VERSION ""

NS_ :

BS_:

BU_:
	NEO
	MCU
	GTW
	EPAS
	DI
	ESP
	SBW
	STW
	APP
	DAS
	XXX

VAL_TABLE_ StW_AnglHP_Spd 16383 "SNA" ;
VAL_TABLE_ DI_aebFaultReason 15 "DI_AEB_FAULT_DAS_REQ_DI_UNAVAIL" 14 "DI_AEB_FAULT_ACCEL_REQ_INVALID" 13 "DI_AEB_FAULT_MIN_TIME_BTWN_EVENTS" 12 "DI_AEB_FAULT_ESP_MIA" 11 "DI_AEB_FAULT_ESP_FAULT" 10 "DI_AEB_FAULT_EPB_NOT_PARKED" 9 "DI_AEB_FAULT_ACCEL_OUT_OF_BOUNDS" 8 "DI_AEB_FAULT_PM_REQUEST" 7 "DI_AEB_FAULT_VEL_EST_ABNORMAL" 6 "DI_AEB_FAULT_DAS_SNA" 5 "DI_AEB_FAULT_DAS_CONTROL_MIA" 4 "DI_AEB_FAULT_SPEED_DELTA" 3 "DI_AEB_FAULT_EBR_FAULT" 2 "DI_AEB_FAULT_PM_MIA" 1 "DI_AEB_FAULT_EPB_MIA" 0 "DI_AEB_FAULT_NONE" ;
VAL_TABLE_ DI_aebLockState 3 "AEB_LOCK_STATE_SNA" 2 "AEB_LOCK_STATE_UNUSED" 1 "AEB_LOCK_STATE_UNLOCKED" 0 "AEB_LOCK_STATE_LOCKED" ;
VAL_TABLE_ DI_aebSmState 7 "DI_AEB_STATE_FAULT" 6 "DI_AEB_STATE_EXIT" 5 "DI_AEB_STATE_STANDSTILL" 4 "DI_AEB_STATE_STOPPING" 3 "DI_AEB_STATE_ENABLE" 2 "DI_AEB_STATE_ENABLE_INIT" 1 "DI_AEB_STATE_STANDBY" 0 "DI_AEB_STATE_UNAVAILABLE" ;
VAL_TABLE_ DI_aebState 7 "AEB_CAN_STATE_SNA" 4 "AEB_CAN_STATE_FAULT" 3 "AEB_CAN_STATE_STANDSTILL" 2 "AEB_CAN_STATE_ENABLED" 1 "AEB_CAN_STATE_STANDBY" 0 "AEB_CAN_STATE_UNAVAILABLE" ;
VAL_TABLE_ DI_epbInterfaceReady 1 "EPB_INTERFACE_READY" 0 "EPB_INTERFACE_NOT_READY" ;
VAL_TABLE_ DI_gear 7 "DI_GEAR_SNA" 4 "DI_GEAR_D" 3 "DI_GEAR_N" 2 "DI_GEAR_R" 1 "DI_GEAR_P" 0 "DI_GEAR_INVALID" ;
VAL_TABLE_ DI_gpoReason 8 "DI_GPO_NUMREASONS" 7 "DI_GPO_CAPACITOR_OVERTEMP" 6 "DI_GPO_NOT_ENOUGH_12V" 5 "DI_GPO_NO_BATTERY_POWER" 4 "DI_GPO_AMBIENT_OVERTEMP" 3 "DI_GPO_FLUID_DELTAT" 2 "DI_GPO_STATOR_OVERTEMP" 1 "DI_GPO_HEATSINK_OVERTEMP" 0 "DI_GPO_OUTLET_OVERTEMP" ;
VAL_TABLE_ DI_immobilizerCondition 1 "DI_IMM_CONDITION_LEARNED" 0 "DI_IMM_CONDITION_VIRGIN_SNA" ;
VAL_TABLE_ DI_immobilizerState 7 "DI_IMM_STATE_FAULT" 6 "DI_IMM_STATE_FAULTRETRY" 5 "DI_IMM_STATE_RESET" 4 "DI_IMM_STATE_LEARN" 3 "DI_IMM_STATE_DISARMED" 2 "DI_IMM_STATE_AUTHENTICATING" 1 "DI_IMM_STATE_REQUEST" 0 "DI_IMM_STATE_INIT_SNA" ;
VAL_TABLE_ DI_limpReason 24 "DI_LIMP_NUMREASONS" 23 "DI_LIMP_CAPACITOR_OVERTEMP" 22 "DI_LIMP_GTW_MIA" 21 "DI_LIMP_TRQCMD_VALIDITY_UNKNOWN" 20 "DI_LIMP_DI_MIA" 19 "DI_LIMP_CONFIG_MISMATCH" 18 "DI_LIMP_HEATSINK_TEMP" 17 "DI_LIMP_PMREQUEST" 16 "DI_LIMP_PMHEARTBEAT" 15 "DI_LIMP_TRQ_CROSS_CHECK" 14 "DI_LIMP_EXTERNAL_COMMAND" 13 "DI_LIMP_WRONG_CS_CALIBRATION" 12 "DI_LIMP_STATOR_TEMP" 11 "DI_LIMP_DELTAT_TOO_NEGATIVE" 10 "DI_LIMP_DELTAT_TOO_POSITIVE" 9 "DI_LIMP_AMBIENT_TEMP" 8 "DI_LIMP_OUTLET_TEMP" 7 "DI_LIMP_LOW_FLOW" 6 "DI_LIMP_BMS_MIA" 5 "DI_LIMP_12V_SUPPLY_UNDERVOLTAGE" 4 "DI_LIMP_NO_FLUID" 3 "DI_LIMP_NO_FUNC_HEATSINK_SENSOR" 2 "DI_LIMP_NO_FUNC_STATORT_SENSOR" 1 "DI_LIMP_BUSV_SENSOR_IRRATIONAL" 0 "DI_LIMP_PHASE_IMBALANCE" ;
VAL_TABLE_ DI_mode 2 "DI_MODE_DYNO" 1 "DI_MODE_DRIVE" 0 "DI_MODE_UNDEF" ;
VAL_TABLE_ DI_motorType 14 "DI_MOTOR_F2AE" 13 "DI_MOTOR_F2AD" 12 "DI_MOTOR_F2AC" 11 "DI_MOTOR_F2AB" 10 "DI_MOTOR_F1AC" 9 "DI_MOTOR_SSR1A" 8 "DI_MOTOR_F1A" 7 "DI_MOTOR_M7M6" 6 "DI_MOTOR_M8A" 5 "DI_MOTOR_M7M5" 4 "DI_MOTOR_M7M4" 3 "DI_MOTOR_M7M3" 2 "DI_MOTOR_ROADSTER_SPORT" 1 "DI_MOTOR_ROADSTER_BASE" 0 "DI_MOTOR_SNA" ;
VAL_TABLE_ DI_speedUnits 1 "DI_SPEED_KPH" 0 "DI_SPEED_MPH" ;
VAL_TABLE_ DI_state 4 "DI_STATE_ENABLE" 3 "DI_STATE_FAULT" 2 "DI_STATE_CLEAR_FAULT" 1 "DI_STATE_STANDBY" 0 "DI_STATE_PREAUTH" ;
VAL_TABLE_ DI_velocityEstimatorState 4 "VE_STATE_BACKUP_MOTOR" 3 "VE_STATE_BACKUP_WHEELS_B" 2 "VE_STATE_BACKUP_WHEELS_A" 1 "VE_STATE_WHEELS_NORMAL" 0 "VE_STATE_NOT_INITIALIZED" ;

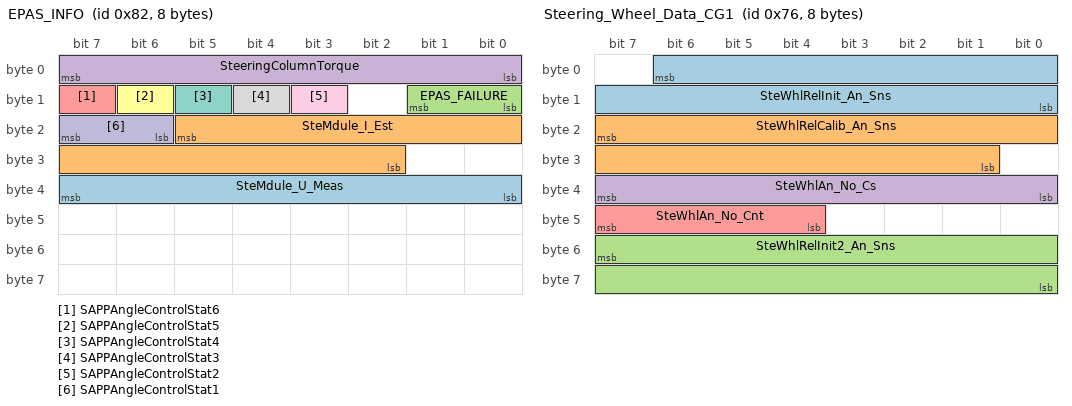
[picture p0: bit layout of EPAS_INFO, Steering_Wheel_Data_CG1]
BO_ 130 EPAS_INFO: 8 XXX
 SG_ SteMdule_U_Meas : 39|8@0+ (0.05,6.0) [0|0] "Volts" XXX
 SG_ SteMdule_I_Est : 21|12@0+ (0.05,-64.0) [0|0] "Amps" XXX
 SG_ EPAS_FAILURE : 9|2@0+ (1,0) [0|0] "" XXX
 SG_ SteeringColumnTorque : 7|8@0+ (0.0625,-8.0) [0|0] "Nm" XXX
 SG_ SAPPAngleControlStat6 : 15|1@0+ (1,0) [0|0] "" XXX
 SG_ SAPPAngleControlStat5 : 14|1@0+ (1,0) [0|0] "" XXX
 SG_ SAPPAngleControlStat4 : 13|1@0+ (1,0) [0|0] "" XXX
 SG_ SAPPAngleControlStat3 : 12|1@0+ (1,0) [0|0] "" XXX
 SG_ SAPPAngleControlStat2 : 11|1@0+ (1,0) [0|0] "" XXX
 SG_ SAPPAngleControlStat1 : 23|2@0+ (1,0) [0|0] "" XXX

BO_ 118 Steering_Wheel_Data_CG1: 8 XXX
 SG_ SteWhlRelInit_An_Sns : 6|15@0+ (0.1,-1600.0) [0|0] "deg" XXX
 SG_ SteWhlRelCalib_An_Sns : 23|15@0+ (0.1,-1600.0) [0|0] "deg" XXX
 SG_ SteWhlRelInit2_An_Sns : 55|16@0+ (0.1,-3200.0) [0|0] "deg" XXX
 SG_ SteWhlAn_No_Cs : 39|8@0+ (1,0) [0|0] "" XXX
 SG_ SteWhlAn_No_Cnt : 47|4@0+ (1,0) [0|0] "Counts" XXX

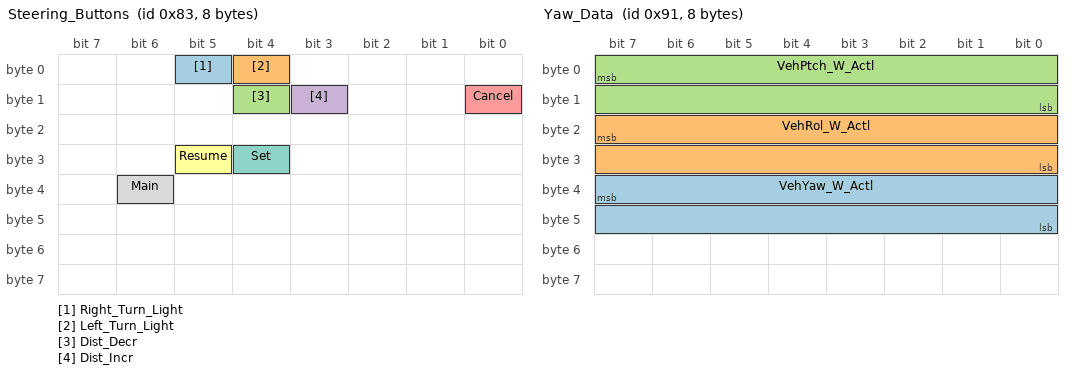
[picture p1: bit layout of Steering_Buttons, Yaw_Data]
BO_ 131 Steering_Buttons: 8 XXX
 SG_ Right_Turn_Light : 5|1@0+ (1,0) [0|0] "" XXX
 SG_ Left_Turn_Light : 4|1@0+ (1,0) [0|0] "" XXX
 SG_ Dist_Decr : 12|1@0+ (1,0) [0|0] "" XXX
 SG_ Dist_Incr : 11|1@0+ (1,0) [0|0] "" XXX
 SG_ Cancel : 8|1@0+ (1,0) [0|0] "" XXX
 SG_ Resume : 29|1@0+ (1,0) [0|0] "" XXX
 SG_ Set : 28|1@0+ (1,0) [0|0] "" XXX
 SG_ Main : 38|1@0+ (1,0) [0|0] "" XXX

BO_ 145 Yaw_Data: 8 XXX
 SG_ VehYaw_W_Actl : 39|16@0+ (0.0002,-6.5) [0|0] "rad/s" XXX
 SG_ VehRol_W_Actl : 23|16@0+ (0.0002,-6.5) [0|0] "rad/s" XXX
 SG_ VehPtch_W_Actl : 7|16@0+ (0.0002,-6.5) [0|0] "rad/s" XXX

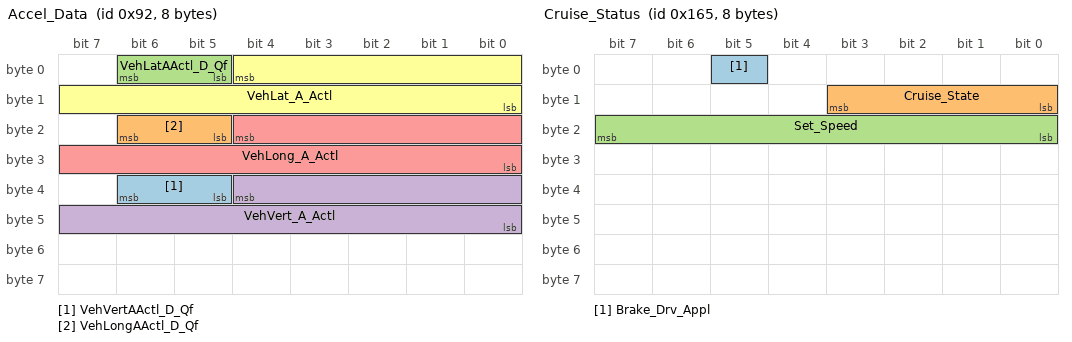
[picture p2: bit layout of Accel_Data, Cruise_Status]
BO_ 146 Accel_Data: 8 XXX
 SG_ VehVertAActl_D_Qf : 38|2@0+ (1,0) [0|0] "" XXX
 SG_ VehLongAActl_D_Qf : 22|2@0+ (1,0) [0|0] "" XXX
 SG_ VehLatAActl_D_Qf : 6|2@0+ (1,0) [0|0] "" XXX
 SG_ VehVert_A_Actl : 36|13@0+ (0.01,-40.0) [0|0] "m/s^2" XXX
 SG_ VehLong_A_Actl : 20|13@0+ (0.01,-40.0) [0|0] "m/s^2" XXX
 SG_ VehLat_A_Actl : 4|13@0+ (0.01,-40.0) [0|0] "m/s^2" XXX

BO_ 357 Cruise_Status: 8 XXX
 SG_ Brake_Drv_Appl : 5|1@0+ (1,0) [0|0] "" XXX
 SG_ Cruise_State : 11|4@0+ (1,0) [0|0] "" XXX
 SG_ Set_Speed : 23|8@0+ (1,0) [0|0] "" XXX

BO_ 516 EngineData_14: 8 XXX
 SG_ ApedPosScal_Pc_Actl : 1|10@0+ (0.1,0) [0|0] "%" XXX

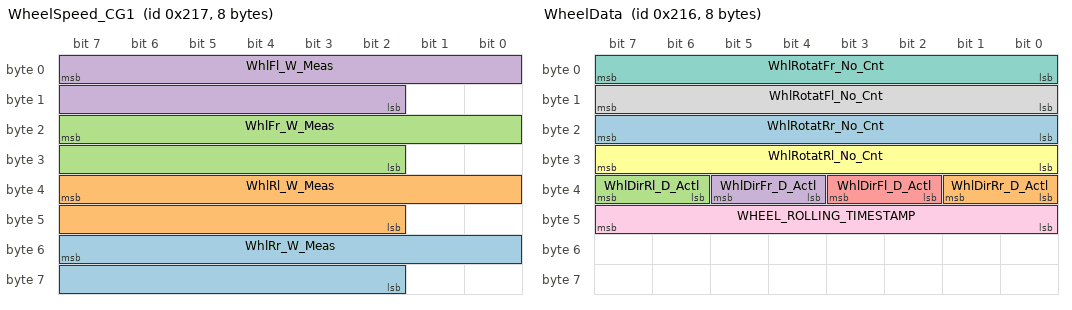
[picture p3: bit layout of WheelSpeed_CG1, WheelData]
BO_ 535 WheelSpeed_CG1: 8 XXX
 SG_ WhlRr_W_Meas : 55|14@0+ (0.04,0) [0|0] "rad/s" XXX
 SG_ WhlRl_W_Meas : 39|14@0+ (0.04,0) [0|0] "rad/s" XXX
 SG_ WhlFr_W_Meas : 23|14@0+ (0.04,0) [0|0] "rad/s" XXX
 SG_ WhlFl_W_Meas : 7|14@0+ (0.04,0) [0|0] "rad/s" XXX

BO_ 534 WheelData: 8 XXX
 SG_ WhlRotatRr_No_Cnt : 23|8@0+ (1,0) [0|0] "" XXX
 SG_ WhlDirRr_D_Actl : 33|2@0+ (1,0) [0|0] "" XXX
 SG_ WhlDirRl_D_Actl : 39|2@0+ (1,0) [0|0] "" XXX
 SG_ WhlDirFr_D_Actl : 37|2@0+ (1,0) [0|0] "" XXX
 SG_ WhlDirFl_D_Actl : 35|2@0+ (1,0) [0|0] "" XXX
 SG_ WhlRotatRl_No_Cnt : 31|8@0+ (1,0) [0|0] "" XXX
 SG_ WhlRotatFr_No_Cnt : 7|8@0+ (1,0) [0|0] "" XXX
 SG_ WhlRotatFl_No_Cnt : 15|8@0+ (1,0) [0|0] "" XXX
 SG_ WHEEL_ROLLING_TIMESTAMP : 47|8@0+ (1,0) [0|0] "" XXX

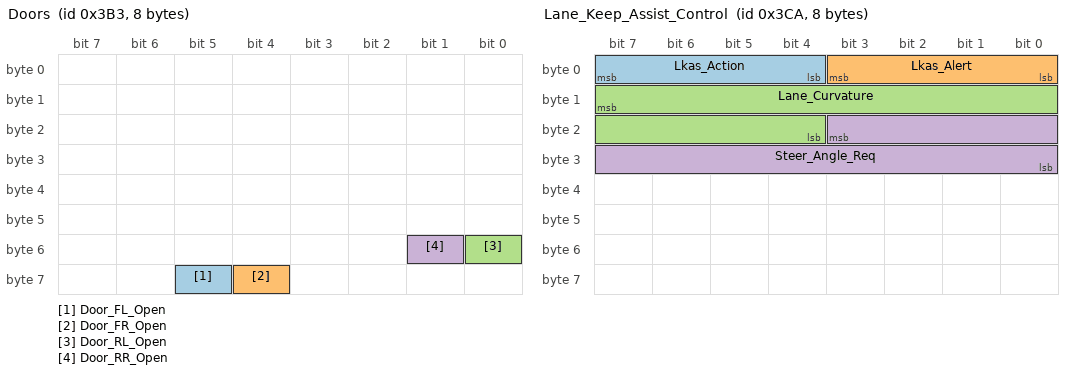
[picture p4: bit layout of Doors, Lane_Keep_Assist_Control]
BO_ 947 Doors: 8 XXX
 SG_ Door_FL_Open : 61|1@0+ (1,0) [0|0] "" XXX
 SG_ Door_FR_Open : 60|1@0+ (1,0) [0|0] "" XXX
 SG_ Door_RL_Open : 48|1@0+ (1,0) [0|0] "" XXX
 SG_ Door_RR_Open : 49|1@0+ (1,0) [0|0] "" XXX

BO_ 963 BCM_to_HS_Body: 8 XXX
 SG_ Brake_Lights : 8|1@0+ (1,0) [0|0] "" XXX

BO_ 970 Lane_Keep_Assist_Control: 8 XXX
 SG_ Lkas_Action : 7|4@0+ (1,0) [0|15] "" XXX
 SG_ Lkas_Alert : 3|4@0+ (1,0) [0|15] "" XXX
 SG_ Lane_Curvature : 15|12@0+ (5e-06,-0.01) [0|0] "1/m" XXX
 SG_ Steer_Angle_Req : 19|12@0+ (0.04297,-88.00445) [0|0] "deg" XXX

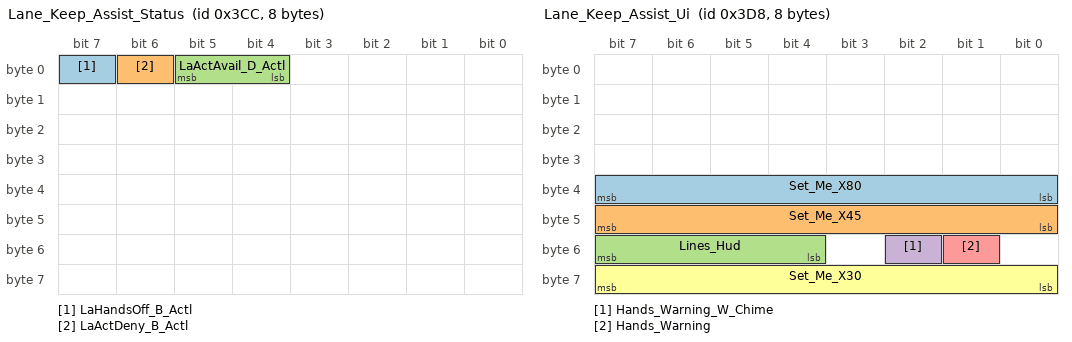
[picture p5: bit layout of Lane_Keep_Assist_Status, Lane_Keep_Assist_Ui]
BO_ 972 Lane_Keep_Assist_Status: 8 XXX
 SG_ LaHandsOff_B_Actl : 7|1@0+ (1,0) [0|0] "" XXX
 SG_ LaActDeny_B_Actl : 6|1@0+ (1,0) [0|0] "" XXX
 SG_ LaActAvail_D_Actl : 5|2@0+ (1,0) [0|0] "" XXX

BO_ 984 Lane_Keep_Assist_Ui: 8 XXX
 SG_ Set_Me_X80 : 39|8@0+ (1,0) [0|255] "" XXX
 SG_ Set_Me_X45 : 47|8@0+ (1,0) [0|255] "" XXX
 SG_ Lines_Hud : 55|4@0+ (1,0) [0|15] "" XXX
 SG_ Hands_Warning_W_Chime : 50|1@0+ (1,0) [0|1] "" XXX
 SG_ Hands_Warning : 49|1@0+ (1,0) [0|1] "" XXX
 SG_ Set_Me_X30 : 63|8@0+ (1,0) [0|255] "" XXX

BU_: K16_BECM K73_TCIC K9_BCM K43_PSCM K17_EBCM K20_ECM K114B_HPCM NEO K124_ASCM EPB
VAL_TABLE_ TurnSignals 2 "Right Turn" 1 "Left Turn" 0 "None" ;
VAL_TABLE_ Intellibeam 1 "Active" 0 "Inactive" ;
VAL_TABLE_ HighBeamsActive 1 "Active" 0 "Inactive" ;
VAL_TABLE_ HighBeamsTemporary 1 "Active" 0 "Inactive" ;
VAL_TABLE_ ACCLeadCar 1 "Present" 0 "Not Present" ;
VAL_TABLE_ ACCCmdActive 1 "Active" 0 "Inactive" ;
VAL_TABLE_ BrakePedalPressed 1 "Pressed" 0 "Depressed" ;
VAL_TABLE_ DistanceButton 1 "Active" 0 "Inactive" ;
VAL_TABLE_ LKAButton 1 "Active" 0 "Inactive" ;
VAL_TABLE_ ACCButtons 6 "Cancel" 5 "Main" 3 "Set" 2 "Resume" 1 "None" ;
VAL_TABLE_ DriveModeButton 1 "Active" 0 "Inactive" ;
VAL_TABLE_ PRNDL 3 "Reverse" 2 "Drive" 1 "Neutral" 0 "Park" ;
VAL_TABLE_ ESPButton 1 "Active" 0 "Inactive" ;
VAL_TABLE_ DoorStatus 1 "Opened" 0 "Closed" ;
VAL_TABLE_ SeatBeltStatus 1 "Latched" 0 "Unlatched" ;
VAL_TABLE_ LKASteeringCmdActive 1 "Active" 0 "Inactive" ;
VAL_TABLE_ ACCGapLevel 3 "Far" 2 "Med" 1 "Near" 0 "Inactive" ;
VAL_TABLE_ GasRegenCmdActiveInv 1 "Inactive" 0 "Active" ;
VAL_TABLE_ GasRegenCmdActive 1 "Active" 0 "Inactive" ;
VAL_TABLE_ LKATorqueDeliveredStatus 3 "Failed" 2 "Temp. Limited" 1 "Active" 0 "Inactive" ;
VAL_TABLE_ HandsOffSWDetectionStatus 1 "Hands On" 0 "Hands Off" ;
VAL_TABLE_ HandsOffSWDetectionMode 2 "Failed" 1 "Enabled" 0 "Disabled" ;

CM_ "AUTOGENERATED FILE, DO NOT EDIT";

CM_ "Imported file _subaru_preglobal_2015.dbc starts here";
CM_ SG_ 320 Off_Throttle_2 "Less sensitive";
CM_ SG_ 320 Throttle_Body "Throttle related";
CM_ SG_ 328 Gear "15 = P, 14 = R, 0 = N, 1-6=gear";
CM_ SG_ 328 Gear_2 "15 = P, 14 = R, 0 = N, 1-6=gear";
CM_ SG_ 353 Cruise_Button "1 = main, 2 = set shallow, 3 = set deep, 4 = resume shallow, 5 resume deep";
CM_ SG_ 354 RPM "20hz version of Transmission_Engine under Transmission";
CM_ SG_ 359 Sig1Right_Depart "right depart, hill steep and seatbelt disengage";
CM_ SG_ 359 LKAS_Inactive_2017 "1 when not steering, 0 when lkas steering";
CM_ SG_ 359 Sig1Right_Depart_Front "object in front, right depart, hill steep and seatbelt disengage alert ";
CM_ SG_ 359 Left_Depart_Front "warning after acceleration into car in front and left depart";
CM_ SG_ 359 Sig1All_Depart "Left and right depart";
CM_ SG_ 359 Sig2All_Depart "Left and right depart";
CM_ SG_ 359 All_depart_2015 "always 1 on 2017";
CM_ SG_ 604 R_APPROACHING "Faster car approaching in far right lane";
CM_ SG_ 604 L_APPROACHING "Faster car approaching in far left lane";
CM_ SG_ 604 R_RCTA "Rear cross traffic alert, only when in R gear";
CM_ SG_ 604 L_RCTA "Rear cross traffic alert, only when in R gear";
CM_ SG_ 642 COUNTER "Affected by signals";
CM_ SG_ 642 SEATBELT_FL "Driver seatbelt";
CM_ SG_ 880 Steering_Voltage_Flat "receives later than 371";
CM_ SG_ 977 UNITS "0 = Metric, 1 = Imperial";

CM_ "subaru_outback_2015.dbc starts here";

CM_ SG_ 358 Disengage_Alert "seatbelt and steep hill disengage";
CM_ SG_ 358 Cruise_Fault "No engagement until restart";
